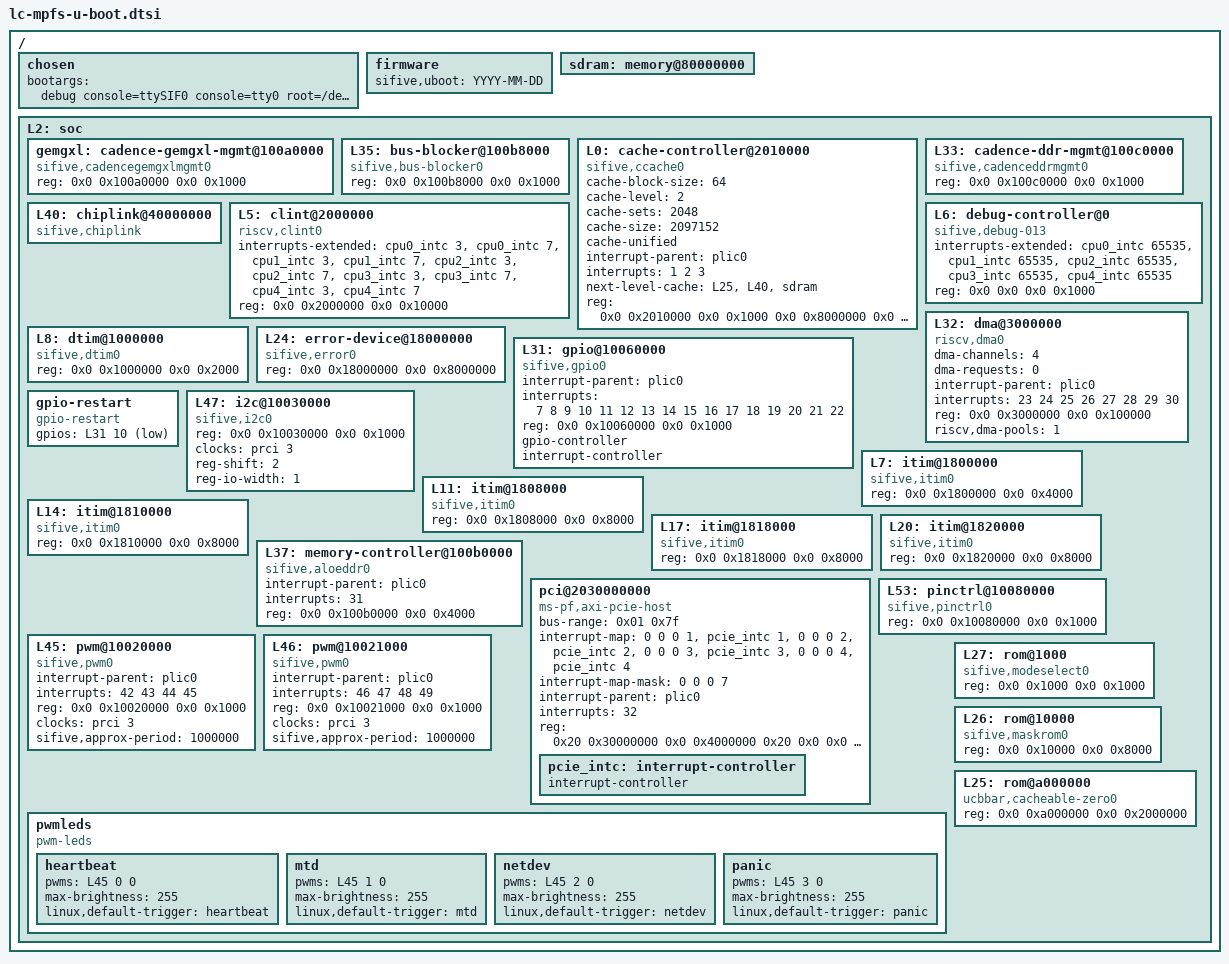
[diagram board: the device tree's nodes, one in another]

/{

        chosen {
                /* bootargs = "console=ttySIF0,921600"; */
                /* bootargs = "debug console=tty0 console=ttySIF0 root=/dev/nvme0n1"; */
                bootargs = "debug console=ttySIF0 console=tty0 root=/dev/nfs ip=dhcp"; 
                /* bootargs = "debug console=ttySIF0,921600 root=/dev/nfs"; */
        };


	firmware {
		sifive,uboot = "YYYY-MM-DD";
	};

	sdram: memory@80000000 {
	};

	L2: soc {
		gemgxl: cadence-gemgxl-mgmt@100a0000 {
			compatible = "sifive,cadencegemgxlmgmt0";
			reg = <0x0 0x100a0000 0x0 0x1000>;
			reg-names = "control";
			#clock-cells = <0>;
		};
		L35: bus-blocker@100b8000 {
			compatible = "sifive,bus-blocker0";
			reg = <0x0 0x100b8000 0x0 0x1000>;
			reg-names = "control";
		};
		L0: cache-controller@2010000 {
			cache-block-size = <64>;
			cache-level = <2>;
			cache-sets = <2048>;
			cache-size = <2097152>;
			cache-unified;
			compatible = "sifive,ccache0", "cache";
			interrupt-parent = <&plic0>;
			interrupts = <1 2 3>;
			next-level-cache = <&L25 &L40 &sdram>;
			reg = <0x0 0x2010000 0x0 0x1000 0x0 0x8000000 0x0 0x2000000>;
			reg-names = "control", "sideband";
		};
		L33: cadence-ddr-mgmt@100c0000 {
			compatible = "sifive,cadenceddrmgmt0";
			reg = <0x0 0x100c0000 0x0 0x1000>;
			reg-names = "control";
		};
		L40: chiplink@40000000 {
			#address-cells = <2>;
			#size-cells = <2>;
			compatible = "sifive,chiplink", "simple-bus";
			ranges = <0x0 0x60000000 0x0 0x60000000 0x0 0x20000000 0x30 0x0 0x30 0x0 0x10 0x0 0x0 0x40000000 0x0 0x40000000 0x0 0x20000000 0x20 0x0 0x20 0x0 0x10 0x0>;
		};
		L5: clint@2000000 {
			compatible = "riscv,clint0";
			interrupts-extended = <&cpu0_intc 3 &cpu0_intc 7 &cpu1_intc 3 &cpu1_intc 7 &cpu2_intc 3 &cpu2_intc 7 &cpu3_intc 3 &cpu3_intc 7 &cpu4_intc 3 &cpu4_intc 7>;
			reg = <0x0 0x2000000 0x0 0x10000>;
			reg-names = "control";
		};
		L6: debug-controller@0 {
			compatible = "sifive,debug-013", "riscv,debug-013";
			interrupts-extended = <&cpu0_intc 65535 &cpu1_intc 65535 &cpu2_intc 65535 &cpu3_intc 65535 &cpu4_intc 65535>;
			reg = <0x0 0x0 0x0 0x1000>;
			reg-names = "control";
		};
		L32: dma@3000000 {
			#dma-cells = <1>;
			compatible = "riscv,dma0";
			dma-channels = <4>;
			dma-requests = <0>;
			interrupt-parent = <&plic0>;
			interrupts = <23 24 25 26 27 28 29 30>;
			reg = <0x0 0x3000000 0x0 0x100000>;
			reg-names = "control";
			riscv,dma-pools = <1>;
		};
		L8: dtim@1000000 {
			compatible = "sifive,dtim0";
			reg = <0x0 0x1000000 0x0 0x2000>;
			reg-names = "mem";
		};
		L24: error-device@18000000 {
			compatible = "sifive,error0";
			reg = <0x0 0x18000000 0x0 0x8000000>;
			reg-names = "mem";
		};
		L31: gpio@10060000 {
			compatible = "sifive,gpio0";
			interrupt-parent = <&plic0>;
			interrupts = <7 8 9 10 11 12 13 14 15 16 17 18 19 20 21 22>;
			reg = <0x0 0x10060000 0x0 0x1000>;
			reg-names = "control";
			gpio-controller;
			#gpio-cells = <2>;
			interrupt-controller;
			#interrupt-cells = <2>;
		};
		gpio-restart {
			compatible = "gpio-restart";
			gpios = <&L31 10 1>;
		};
		L47: i2c@10030000 {
			compatible = "sifive,i2c0", "opencores,i2c-ocores";
			reg = <0x0 0x10030000 0x0 0x1000>;
			reg-names = "control";
			clocks = <&prci 3>;

			reg-shift = <2>;
			reg-io-width = <1>;

			#address-cells = <1>;
			#size-cells = <0>;
		};
		L7: itim@1800000 {
			compatible = "sifive,itim0";
			reg = <0x0 0x1800000 0x0 0x4000>;
			reg-names = "mem";
		};
		L11: itim@1808000 {
			compatible = "sifive,itim0";
			reg = <0x0 0x1808000 0x0 0x8000>;
			reg-names = "mem";
		};
		L14: itim@1810000 {
			compatible = "sifive,itim0";
			reg = <0x0 0x1810000 0x0 0x8000>;
			reg-names = "mem";
		};
		L17: itim@1818000 {
			compatible = "sifive,itim0";
			reg = <0x0 0x1818000 0x0 0x8000>;
			reg-names = "mem";
		};
		L20: itim@1820000 {
			compatible = "sifive,itim0";
			reg = <0x0 0x1820000 0x0 0x8000>;
			reg-names = "mem";
		};
		L37: memory-controller@100b0000 {
			compatible = "sifive,aloeddr0";
			interrupt-parent = <&plic0>;
			interrupts = <31>;
			reg = <0x0 0x100b0000 0x0 0x4000>;
			reg-names = "control";
		};
		pci@2030000000 {
			#address-cells = <3>;
			#interrupt-cells = <1>;
			#size-cells = <2>;
			compatible = "ms-pf,axi-pcie-host";
			device_type = "pci";
			bus-range = <0x01 0x7f>;
			interrupt-map = <0 0 0 1 &pcie_intc 1>,
                                        <0 0 0 2 &pcie_intc 2>,
                                        <0 0 0 3 &pcie_intc 3>,
                                        <0 0 0 4 &pcie_intc 4>;
			interrupt-map-mask = <0 0 0 7>;
			interrupt-parent = <&plic0>;
			interrupts = <32>;
                        ranges = <0x3000000 0x0 0x40000000 0x0 0x40000000 0x0 0x20000000>;
                        reg = <0x20 0x30000000 0x0 0x4000000 0x20 0x0 0x0 0x100000>;
                        reg-names = "control", "apb";
			pcie_intc: interrupt-controller {
				#address-cells = <0>;
				#interrupt-cells = <1>;
				interrupt-controller;
			};
		};
		L53: pinctrl@10080000 {
			compatible = "sifive,pinctrl0";
			reg = <0x0 0x10080000 0x0 0x1000>;
			reg-names = "control";
		};
		L45: pwm@10020000 {
			compatible = "sifive,pwm0";
			interrupt-parent = <&plic0>;
			interrupts = <42 43 44 45>;
			reg = <0x0 0x10020000 0x0 0x1000>;
			reg-names = "control";
			clocks = <&prci 3>;
			sifive,approx-period = <1000000>;
			#pwm-cells = <2>;
		};
		L46: pwm@10021000 {
			compatible = "sifive,pwm0";
			interrupt-parent = <&plic0>;
			interrupts = <46 47 48 49>;
			reg = <0x0 0x10021000 0x0 0x1000>;
			reg-names = "control";
			clocks = <&prci 3>;
			sifive,approx-period = <1000000>;
			#pwm-cells = <2>;
		};
		pwmleds {
			compatible = "pwm-leds";
			heartbeat {
				pwms = <&L45 0 0>;
				max-brightness = <255>;
				linux,default-trigger = "heartbeat";
			};
			mtd {
				pwms = <&L45 1 0>;
				max-brightness = <255>;
				linux,default-trigger = "mtd";
			};
			netdev {
				pwms = <&L45 2 0>;
				max-brightness = <255>;
				linux,default-trigger = "netdev";
			};
			panic {
				pwms = <&L45 3 0>;
				max-brightness = <255>;
				linux,default-trigger = "panic";
			};
			/* These LEDs are on the tester board */
/*
			testled {
				pwms = <&L46 0 0>;
				max-brightness = <255>;
			};
			green {
				pwms = <&L46 1 0>;
				max-brightness = <255>;
			};
			red {
				pwms = <&L46 2 0>;
				max-brightness = <255>;
			};
			blue {
				pwms = <&L46 3 0>;
				max-brightness = <255>;
			};
*/
		};
		L27: rom@1000 {
			compatible = "sifive,modeselect0";
			reg = <0x0 0x1000 0x0 0x1000>;
			reg-names = "mem";
		};
		L26: rom@10000 {
			compatible = "sifive,maskrom0";
			reg = <0x0 0x10000 0x0 0x8000>;
			reg-names = "mem";
		};
		L25: rom@a000000 {
			compatible = "ucbbar,cacheable-zero0";
			reg = <0x0 0xa000000 0x0 0x2000000>;
			reg-names = "mem";
		};
	};
};
